AUTOSAR XML (schema 4-0-3)
standard types defined: Boolean, UInt16, UInt32
package /AUTOSAR_Platform/DataConstrs
  range DC_Boolean: raw 0..1
  range DC_UInt16: raw 0..65535
package /PATAC/MSM/ComponentTypes
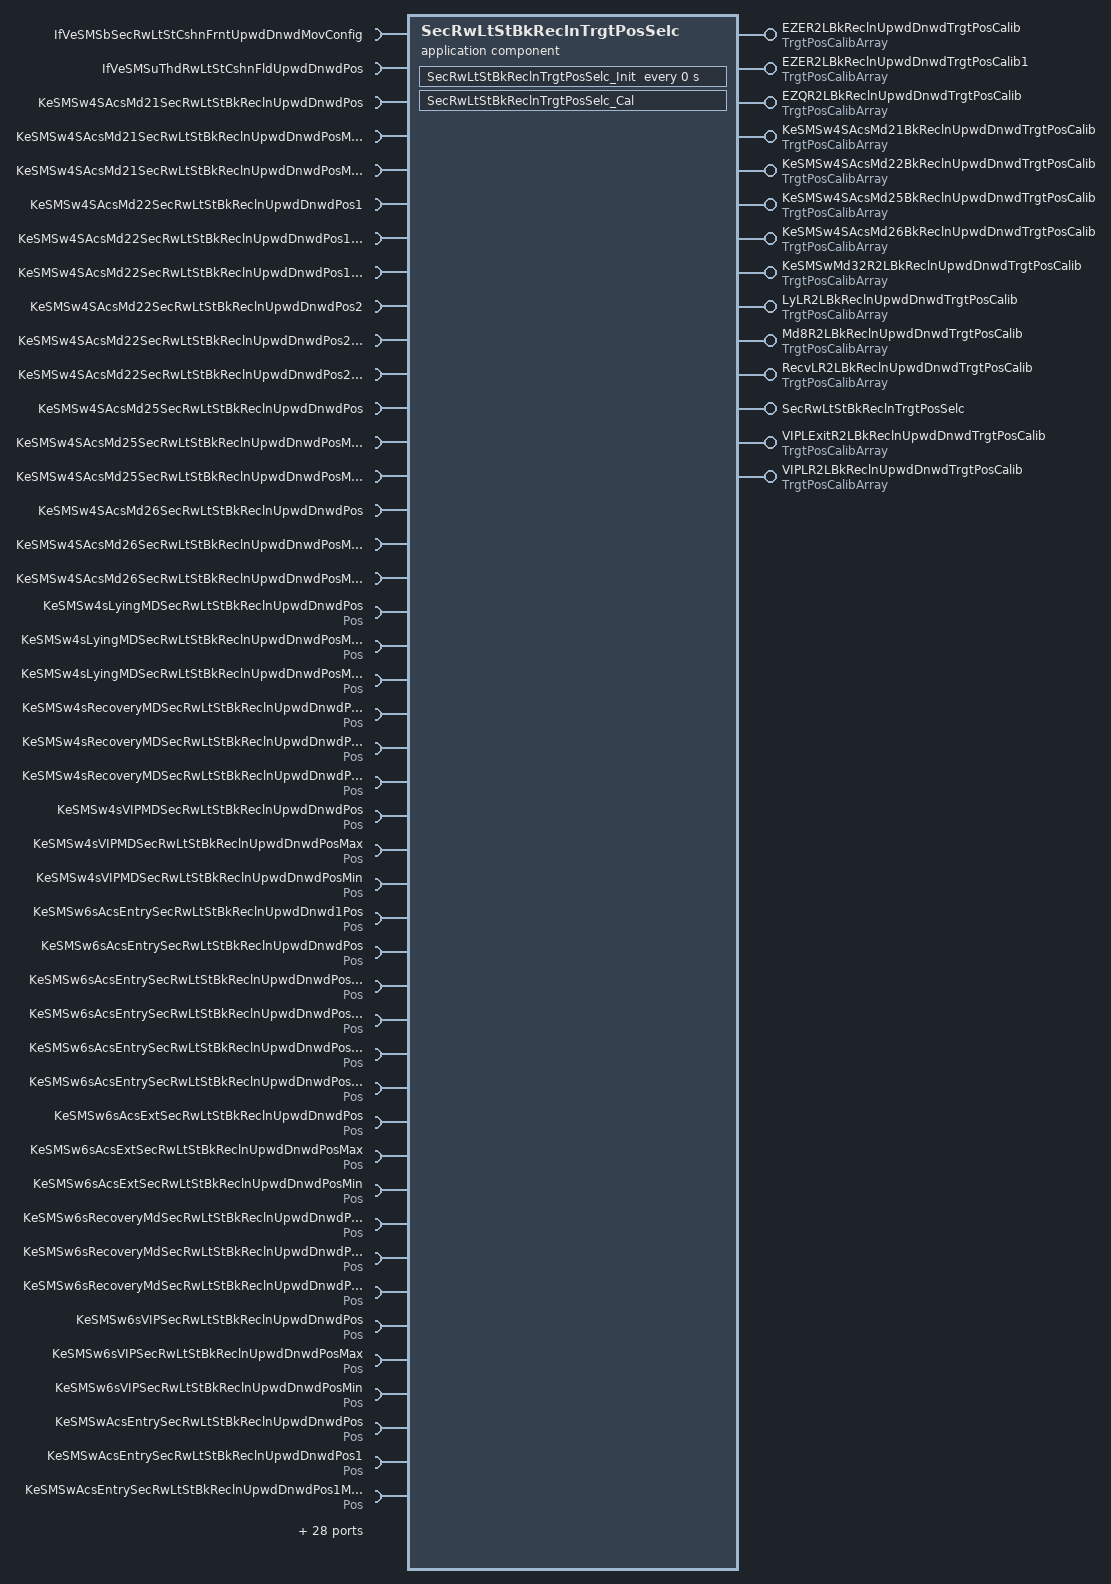
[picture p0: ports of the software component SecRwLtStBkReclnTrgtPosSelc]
  application sw component type SecRwLtStBkReclnTrgtPosSelc
    14 x provide port:
      EZER2LBkReclnUpwdDnwdTrgtPosCalib: nonqueued-sender-com-spec{data-element=TrgtPosArray, init-value=[4095, 4095, 4095]}, provided-interface=TrgtPosCalibArray
      EZER2LBkReclnUpwdDnwdTrgtPosCalib1: nonqueued-sender-com-spec{data-element=TrgtPosArray, init-value=[4095, 4095, 4095]}, provided-interface=TrgtPosCalibArray
      EZQR2LBkReclnUpwdDnwdTrgtPosCalib: nonqueued-sender-com-spec{data-element=TrgtPosArray, init-value=[4095, 4095, 4095]}, provided-interface=TrgtPosCalibArray
      KeSMSw4SAcsMd21BkReclnUpwdDnwdTrgtPosCalib: nonqueued-sender-com-spec{data-element=TrgtPosArray, init-value=[4095, 4095, 4095]}, provided-interface=TrgtPosCalibArray
      KeSMSw4SAcsMd22BkReclnUpwdDnwdTrgtPosCalib: nonqueued-sender-com-spec{data-element=TrgtPosArray, init-value=[4095, 4095, 4095]}, provided-interface=TrgtPosCalibArray
      KeSMSw4SAcsMd25BkReclnUpwdDnwdTrgtPosCalib: nonqueued-sender-com-spec{data-element=TrgtPosArray, init-value=[4095, 4095, 4095]}, provided-interface=TrgtPosCalibArray
      KeSMSw4SAcsMd26BkReclnUpwdDnwdTrgtPosCalib: nonqueued-sender-com-spec{data-element=TrgtPosArray, init-value=[4095, 4095, 4095]}, provided-interface=TrgtPosCalibArray
      KeSMSwMd32R2LBkReclnUpwdDnwdTrgtPosCalib: nonqueued-sender-com-spec{data-element=TrgtPosArray, init-value=[4095, 4095, 4095]}, provided-interface=TrgtPosCalibArray
      LyLR2LBkReclnUpwdDnwdTrgtPosCalib: nonqueued-sender-com-spec{data-element=TrgtPosArray, init-value=[4095, 4095, 4095]}, provided-interface=TrgtPosCalibArray
      Md8R2LBkReclnUpwdDnwdTrgtPosCalib: nonqueued-sender-com-spec{data-element=TrgtPosArray, init-value=[4095, 4095, 4095]}, provided-interface=TrgtPosCalibArray
      RecvLR2LBkReclnUpwdDnwdTrgtPosCalib: nonqueued-sender-com-spec{data-element=TrgtPosArray, init-value=[4095, 4095, 4095]}, provided-interface=TrgtPosCalibArray
      SecRwLtStBkReclnTrgtPosSelc: server-com-spec{operation=Cal, queue-length=1}, provided-interface=SecRwLtStBkReclnTrgtPosSelc
      VIPLExitR2LBkReclnUpwdDnwdTrgtPosCalib: nonqueued-sender-com-spec{data-element=TrgtPosArray, init-value=[4095, 4095, 4095]}, provided-interface=TrgtPosCalibArray
      VIPLR2LBkReclnUpwdDnwdTrgtPosCalib: nonqueued-sender-com-spec{data-element=TrgtPosArray, init-value=[4095, 4095, 4095]}, provided-interface=TrgtPosCalibArray
    72 x require port:
      IfVeSMSbSecRwLtStCshnFrntUpwdDnwdMovConfig: nonqueued-receiver-com-spec{data-element=IfVeSMSbSecRwLtStCshnFrntUpwdDnwdMovConfig/Val, filter=data-filter-type=ALWAYS, init-value=0}, required-interface=IfVeSMSbSecRwLtStCshnFrntUpwdDnwdMovConfig
      IfVeSMSuThdRwLtStCshnFldUpwdDnwdPos: nonqueued-receiver-com-spec{data-element=IfVeSMSuThdRwLtStCshnFldUpwdDnwdPos/Val, filter=data-filter-type=ALWAYS, init-value=0}, required-interface=IfVeSMSuThdRwLtStCshnFldUpwdDnwdPos
      KeSMSw4SAcsMd21SecRwLtStBkReclnUpwdDnwdPos: parameter-require-com-spec{init-value=0, parameter=KeSMSw4SAcsMd21SecRwLtStBkReclnUpwdDnwdPos/Val}, required-interface=KeSMSw4SAcsMd21SecRwLtStBkReclnUpwdDnwdPos
      KeSMSw4SAcsMd21SecRwLtStBkReclnUpwdDnwdPosMax: parameter-require-com-spec{init-value=0, parameter=KeSMSw4SAcsMd21SecRwLtStBkReclnUpwdDnwdPosMax/Val}, required-interface=KeSMSw4SAcsMd21SecRwLtStBkReclnUpwdDnwdPosMax
      KeSMSw4SAcsMd21SecRwLtStBkReclnUpwdDnwdPosMin: parameter-require-com-spec{init-value=0, parameter=KeSMSw4SAcsMd21SecRwLtStBkReclnUpwdDnwdPosMin/Val}, required-interface=KeSMSw4SAcsMd21SecRwLtStBkReclnUpwdDnwdPosMin
      KeSMSw4SAcsMd22SecRwLtStBkReclnUpwdDnwdPos1: parameter-require-com-spec{init-value=0, parameter=KeSMSw4SAcsMd22SecRwLtStBkReclnUpwdDnwdPos1/Val}, required-interface=KeSMSw4SAcsMd22SecRwLtStBkReclnUpwdDnwdPos1
      KeSMSw4SAcsMd22SecRwLtStBkReclnUpwdDnwdPos1Max: parameter-require-com-spec{init-value=0, parameter=KeSMSw4SAcsMd22SecRwLtStBkReclnUpwdDnwdPos1Max/Val}, required-interface=KeSMSw4SAcsMd22SecRwLtStBkReclnUpwdDnwdPos1Max
      KeSMSw4SAcsMd22SecRwLtStBkReclnUpwdDnwdPos1Min: parameter-require-com-spec{init-value=0, parameter=KeSMSw4SAcsMd22SecRwLtStBkReclnUpwdDnwdPos1Min/Val}, required-interface=KeSMSw4SAcsMd22SecRwLtStBkReclnUpwdDnwdPos1Min
      KeSMSw4SAcsMd22SecRwLtStBkReclnUpwdDnwdPos2: parameter-require-com-spec{init-value=0, parameter=KeSMSw4SAcsMd22SecRwLtStBkReclnUpwdDnwdPos2/Val}, required-interface=KeSMSw4SAcsMd22SecRwLtStBkReclnUpwdDnwdPos2
      KeSMSw4SAcsMd22SecRwLtStBkReclnUpwdDnwdPos2Max: parameter-require-com-spec{init-value=0, parameter=KeSMSw4SAcsMd22SecRwLtStBkReclnUpwdDnwdPos2Max/Val}, required-interface=KeSMSw4SAcsMd22SecRwLtStBkReclnUpwdDnwdPos2Max
      KeSMSw4SAcsMd22SecRwLtStBkReclnUpwdDnwdPos2Min: parameter-require-com-spec{init-value=0, parameter=KeSMSw4SAcsMd22SecRwLtStBkReclnUpwdDnwdPos2Min/Val}, required-interface=KeSMSw4SAcsMd22SecRwLtStBkReclnUpwdDnwdPos2Min
      KeSMSw4SAcsMd25SecRwLtStBkReclnUpwdDnwdPos: parameter-require-com-spec{init-value=0, parameter=KeSMSw4SAcsMd25SecRwLtStBkReclnUpwdDnwdPos/Val}, required-interface=KeSMSw4SAcsMd25SecRwLtStBkReclnUpwdDnwdPos
      KeSMSw4SAcsMd25SecRwLtStBkReclnUpwdDnwdPosMax: parameter-require-com-spec{init-value=0, parameter=KeSMSw4SAcsMd25SecRwLtStBkReclnUpwdDnwdPosMax/Val}, required-interface=KeSMSw4SAcsMd25SecRwLtStBkReclnUpwdDnwdPosMax
      KeSMSw4SAcsMd25SecRwLtStBkReclnUpwdDnwdPosMin: parameter-require-com-spec{init-value=0, parameter=KeSMSw4SAcsMd25SecRwLtStBkReclnUpwdDnwdPosMin/Val}, required-interface=KeSMSw4SAcsMd25SecRwLtStBkReclnUpwdDnwdPosMin
      KeSMSw4SAcsMd26SecRwLtStBkReclnUpwdDnwdPos: parameter-require-com-spec{init-value=0, parameter=KeSMSw4SAcsMd26SecRwLtStBkReclnUpwdDnwdPos/Val}, required-interface=KeSMSw4SAcsMd26SecRwLtStBkReclnUpwdDnwdPos
      KeSMSw4SAcsMd26SecRwLtStBkReclnUpwdDnwdPosMax: parameter-require-com-spec{init-value=0, parameter=KeSMSw4SAcsMd26SecRwLtStBkReclnUpwdDnwdPosMax/Val}, required-interface=KeSMSw4SAcsMd26SecRwLtStBkReclnUpwdDnwdPosMax
      KeSMSw4SAcsMd26SecRwLtStBkReclnUpwdDnwdPosMin: parameter-require-com-spec{init-value=0, parameter=KeSMSw4SAcsMd26SecRwLtStBkReclnUpwdDnwdPosMin/Val}, required-interface=KeSMSw4SAcsMd26SecRwLtStBkReclnUpwdDnwdPosMin
      KeSMSw4sLyingMDSecRwLtStBkReclnUpwdDnwdPos: parameter-require-com-spec{init-value=0, parameter=Pos/Val}, required-interface=Pos
      KeSMSw4sLyingMDSecRwLtStBkReclnUpwdDnwdPosMax: parameter-require-com-spec{init-value=0, parameter=Pos/Val}, required-interface=Pos
      KeSMSw4sLyingMDSecRwLtStBkReclnUpwdDnwdPosMin: parameter-require-com-spec{init-value=0, parameter=Pos/Val}, required-interface=Pos
      KeSMSw4sRecoveryMDSecRwLtStBkReclnUpwdDnwdPos: parameter-require-com-spec{init-value=0, parameter=Pos/Val}, required-interface=Pos
      KeSMSw4sRecoveryMDSecRwLtStBkReclnUpwdDnwdPosMax: parameter-require-com-spec{init-value=0, parameter=Pos/Val}, required-interface=Pos
      KeSMSw4sRecoveryMDSecRwLtStBkReclnUpwdDnwdPosMin: parameter-require-com-spec{init-value=0, parameter=Pos/Val}, required-interface=Pos
      KeSMSw4sVIPMDSecRwLtStBkReclnUpwdDnwdPos: parameter-require-com-spec{init-value=0, parameter=Pos/Val}, required-interface=Pos
      KeSMSw4sVIPMDSecRwLtStBkReclnUpwdDnwdPosMax: parameter-require-com-spec{init-value=0, parameter=Pos/Val}, required-interface=Pos
      KeSMSw4sVIPMDSecRwLtStBkReclnUpwdDnwdPosMin: parameter-require-com-spec{init-value=0, parameter=Pos/Val}, required-interface=Pos
      KeSMSw6sAcsEntrySecRwLtStBkReclnUpwdDnwd1Pos: parameter-require-com-spec{init-value=1280, parameter=Pos/Val}, required-interface=Pos
      KeSMSw6sAcsEntrySecRwLtStBkReclnUpwdDnwdPos: parameter-require-com-spec{init-value=1280, parameter=Pos/Val}, required-interface=Pos
      KeSMSw6sAcsEntrySecRwLtStBkReclnUpwdDnwdPos1Max: parameter-require-com-spec{init-value=1280, parameter=Pos/Val}, required-interface=Pos
      KeSMSw6sAcsEntrySecRwLtStBkReclnUpwdDnwdPos1Min: parameter-require-com-spec{init-value=0, parameter=Pos/Val}, required-interface=Pos
      KeSMSw6sAcsEntrySecRwLtStBkReclnUpwdDnwdPosMax: parameter-require-com-spec{init-value=1280, parameter=Pos/Val}, required-interface=Pos
      KeSMSw6sAcsEntrySecRwLtStBkReclnUpwdDnwdPosMin: parameter-require-com-spec{init-value=0, parameter=Pos/Val}, required-interface=Pos
      KeSMSw6sAcsExtSecRwLtStBkReclnUpwdDnwdPos: parameter-require-com-spec{init-value=1280, parameter=Pos/Val}, required-interface=Pos
      KeSMSw6sAcsExtSecRwLtStBkReclnUpwdDnwdPosMax: parameter-require-com-spec{init-value=1280, parameter=Pos/Val}, required-interface=Pos
      KeSMSw6sAcsExtSecRwLtStBkReclnUpwdDnwdPosMin: parameter-require-com-spec{init-value=0, parameter=Pos/Val}, required-interface=Pos
      KeSMSw6sRecoveryMdSecRwLtStBkReclnUpwdDnwdPos: parameter-require-com-spec{init-value=1268, parameter=Pos/Val}, required-interface=Pos
      KeSMSw6sRecoveryMdSecRwLtStBkReclnUpwdDnwdPosMax: parameter-require-com-spec{init-value=1268, parameter=Pos/Val}, required-interface=Pos
      KeSMSw6sRecoveryMdSecRwLtStBkReclnUpwdDnwdPosMin: parameter-require-com-spec{init-value=0, parameter=Pos/Val}, required-interface=Pos
      KeSMSw6sVIPSecRwLtStBkReclnUpwdDnwdPos: parameter-require-com-spec{init-value=1960, parameter=Pos/Val}, required-interface=Pos
      KeSMSw6sVIPSecRwLtStBkReclnUpwdDnwdPosMax: parameter-require-com-spec{init-value=1960, parameter=Pos/Val}, required-interface=Pos
      KeSMSw6sVIPSecRwLtStBkReclnUpwdDnwdPosMin: parameter-require-com-spec{init-value=1960, parameter=Pos/Val}, required-interface=Pos
      KeSMSwAcsEntrySecRwLtStBkReclnUpwdDnwdPos: parameter-require-com-spec{init-value=1280, parameter=Pos/Val}, required-interface=Pos
      KeSMSwAcsEntrySecRwLtStBkReclnUpwdDnwdPos1: parameter-require-com-spec{init-value=1280, parameter=Pos/Val}, required-interface=Pos
      KeSMSwAcsEntrySecRwLtStBkReclnUpwdDnwdPos1Max: parameter-require-com-spec{init-value=1280, parameter=Pos/Val}, required-interface=Pos
      KeSMSwAcsEntrySecRwLtStBkReclnUpwdDnwdPos1Min: parameter-require-com-spec{init-value=0, parameter=Pos/Val}, required-interface=Pos
      KeSMSwAcsEntrySecRwLtStBkReclnUpwdDnwdPosMax: parameter-require-com-spec{init-value=1280, parameter=Pos/Val}, required-interface=Pos
      KeSMSwAcsEntrySecRwLtStBkReclnUpwdDnwdPosMin: parameter-require-com-spec{init-value=0, parameter=Pos/Val}, required-interface=Pos
      KeSMSwAcsExtSecRwLtStBkReclnUpwdDnwdPos: parameter-require-com-spec{init-value=1280, parameter=Pos/Val}, required-interface=Pos
      KeSMSwAcsExtSecRwLtStBkReclnUpwdDnwdPosMax: parameter-require-com-spec{init-value=1280, parameter=Pos/Val}, required-interface=Pos
      KeSMSwAcsExtSecRwLtStBkReclnUpwdDnwdPosMin: parameter-require-com-spec{init-value=0, parameter=Pos/Val}, required-interface=Pos
      KeSMSwAcsMd32SecRwLtStBkReclnUpwdDnwdPos: parameter-require-com-spec{init-value=0, parameter=Pos/Val}, required-interface=Pos
      KeSMSwAcsMd32SecRwLtStBkReclnUpwdDnwdPos1: parameter-require-com-spec{init-value=0, parameter=Pos/Val}, required-interface=Pos
      KeSMSwAcsMd32SecRwLtStBkReclnUpwdDnwdPos1Max: parameter-require-com-spec{init-value=0, parameter=Pos/Val}, required-interface=Pos
      KeSMSwAcsMd32SecRwLtStBkReclnUpwdDnwdPos1Min: parameter-require-com-spec{init-value=0, parameter=Pos/Val}, required-interface=Pos
      KeSMSwAcsMd32SecRwLtStBkReclnUpwdDnwdPosMax: parameter-require-com-spec{init-value=0, parameter=Pos/Val}, required-interface=Pos
      KeSMSwAcsMd32SecRwLtStBkReclnUpwdDnwdPosMin: parameter-require-com-spec{init-value=0, parameter=Pos/Val}, required-interface=Pos
      KeSMSwAcsMd8SecRwLtStBkReclnUpwdDnwdPos: parameter-require-com-spec{init-value=0, parameter=Pos/Val}, required-interface=Pos
      KeSMSwAcsMd8SecRwLtStBkReclnUpwdDnwdPosMax: parameter-require-com-spec{init-value=0, parameter=Pos/Val}, required-interface=Pos
      KeSMSwAcsMd8SecRwLtStBkReclnUpwdDnwdPosMin: parameter-require-com-spec{init-value=0, parameter=Pos/Val}, required-interface=Pos
      KeSMSwRecoveryMdSecRwLtStBkReclnUpwdDnwdPos: parameter-require-com-spec{init-value=1268, parameter=Pos/Val}, required-interface=Pos
      KeSMSwRecoveryMdSecRwLtStBkReclnUpwdDnwdPosMax: parameter-require-com-spec{init-value=1268, parameter=Pos/Val}, required-interface=Pos
      KeSMSwRecoveryMdSecRwLtStBkReclnUpwdDnwdPosMin: parameter-require-com-spec{init-value=0, parameter=Pos/Val}, required-interface=Pos
      KeSMSwVIPSecRwLtStBkReclnUpwdDnwdPos: parameter-require-com-spec{init-value=1960, parameter=Pos/Val}, required-interface=Pos
      KeSMSwVIPSecRwLtStBkReclnUpwdDnwdPosMax: parameter-require-com-spec{init-value=1960, parameter=Pos/Val}, required-interface=Pos
      KeSMSwVIPSecRwLtStBkReclnUpwdDnwdPosMin: parameter-require-com-spec{init-value=1960, parameter=Pos/Val}, required-interface=Pos
      modestate32: nonqueued-receiver-com-spec{data-element=modestate32/Val, filter=data-filter-type=ALWAYS, init-value=0}, required-interface=modestate32
      R2LBkReclinFirstStepPassFlg: nonqueued-receiver-com-spec{data-element=R2LBkReclinFirstStepPassFlg/Val, filter=data-filter-type=ALWAYS, init-value=0}, required-interface=R2LBkReclinFirstStepPassFlg
      R2LMdSeatOccupied: nonqueued-receiver-com-spec{data-element=MdSeatOccupied/Val, filter=data-filter-type=ALWAYS, init-value=0}, required-interface=MdSeatOccupied
      StNumFlg: required-interface=StNumFlg
        required-com-specs:
          data-element=Is4s, filter=data-filter-type=ALWAYS, init-value=0
          data-element=Is6s, filter=data-filter-type=ALWAYS, init-value=0
          data-element=Is6s7s, filter=data-filter-type=ALWAYS, init-value=0
          data-element=Is7s, filter=data-filter-type=ALWAYS, init-value=0
      ThdRwLtStCshnFldStgDone: nonqueued-receiver-com-spec{data-element=StgDone/Val, filter=data-filter-type=ALWAYS, init-value=0}, required-interface=StgDone
      VIPL557TrgtPos: required-com-specs=[VIPL557TrgtPos/Get, VIPL557TrgtPos/Set], required-interface=VIPL557TrgtPos
      VIPLExit557TrgtPos: required-com-specs=[VIPLExit557TrgtPos/Get, VIPLExit557TrgtPos/Set], required-interface=VIPLExit557TrgtPos
    behavior SecRwLtStBkReclnTrgtPosSelc_InternalBehavior
      operation invoked event OIT_SecRwLtStBkReclnTrgtPosSelc_Cal_SecRwLtStBkReclnTrgtPosSelc_Cal: start-on-event=SecRwLtStBkReclnTrgtPosSelc_Cal, operation=SecRwLtStBkReclnTrgtPosSelc.Cal
      timing event SecRwLtStBkReclnTrgtPosSelc_InitEvent: start-on-event=SecRwLtStBkReclnTrgtPosSelc_Init, period=0
      runnable SecRwLtStBkReclnTrgtPosSelc_Cal
        data-receive-point-by-arguments:
          10 x access:
            REC_IfVeSMSbSecRwLtStCshnFrntUpwdDnwdMovConfig_Val: accessed-variable=IfVeSMSbSecRwLtStCshnFrntUpwdDnwdMovConfig.Val
            REC_IfVeSMSuThdRwLtStCshnFldUpwdDnwdPos_Val: accessed-variable=IfVeSMSuThdRwLtStCshnFldUpwdDnwdPos.Val
            REC_modestate32_Val: accessed-variable=modestate32.Val
            REC_R2LBkReclinFirstStepPassFlg_Val: accessed-variable=R2LBkReclinFirstStepPassFlg.Val
            REC_R2LMdSeatOccupied_Val: accessed-variable=R2LMdSeatOccupied.Val
            REC_StNumFlg_Is4s: accessed-variable=StNumFlg.Is4s
            REC_StNumFlg_Is6s: accessed-variable=StNumFlg.Is6s
            REC_StNumFlg_Is6s7s: accessed-variable=StNumFlg.Is6s7s
            REC_StNumFlg_Is7s: accessed-variable=StNumFlg.Is7s
            REC_ThdRwLtStCshnFldStgDone_Val: accessed-variable=ThdRwLtStCshnFldStgDone.Val
        data-send-points:
          13 x access:
            SEND_EZER2LBkReclnUpwdDnwdTrgtPosCalib_TrgtPosArray: accessed-variable=EZER2LBkReclnUpwdDnwdTrgtPosCalib.TrgtPosArray
            SEND_EZER2LBkReclnUpwdDnwdTrgtPosCalib1_TrgtPosArray: accessed-variable=EZER2LBkReclnUpwdDnwdTrgtPosCalib1.TrgtPosArray
            SEND_EZQR2LBkReclnUpwdDnwdTrgtPosCalib_TrgtPosArray: accessed-variable=EZQR2LBkReclnUpwdDnwdTrgtPosCalib.TrgtPosArray
            SEND_KeSMSw4SAcsMd21BkReclnUpwdDnwdTrgtPosCalib_TrgtPosArray: accessed-variable=KeSMSw4SAcsMd21BkReclnUpwdDnwdTrgtPosCalib.TrgtPosArray
            SEND_KeSMSw4SAcsMd22BkReclnUpwdDnwdTrgtPosCalib_TrgtPosArray: accessed-variable=KeSMSw4SAcsMd22BkReclnUpwdDnwdTrgtPosCalib.TrgtPosArray
            SEND_KeSMSw4SAcsMd25BkReclnUpwdDnwdTrgtPosCalib_TrgtPosArray: accessed-variable=KeSMSw4SAcsMd25BkReclnUpwdDnwdTrgtPosCalib.TrgtPosArray
            SEND_KeSMSw4SAcsMd26BkReclnUpwdDnwdTrgtPosCalib_TrgtPosArray: accessed-variable=KeSMSw4SAcsMd26BkReclnUpwdDnwdTrgtPosCalib.TrgtPosArray
            SEND_KeSMSwMd32R2LBkReclnUpwdDnwdTrgtPosCalib_TrgtPosArray: accessed-variable=KeSMSwMd32R2LBkReclnUpwdDnwdTrgtPosCalib.TrgtPosArray
            SEND_LyLR2LBkReclnUpwdDnwdTrgtPosCalib_TrgtPosArray: accessed-variable=LyLR2LBkReclnUpwdDnwdTrgtPosCalib.TrgtPosArray
            SEND_Md8R2LBkReclnUpwdDnwdTrgtPosCalib_TrgtPosArray: accessed-variable=Md8R2LBkReclnUpwdDnwdTrgtPosCalib.TrgtPosArray
            SEND_RecvLR2LBkReclnUpwdDnwdTrgtPosCalib_TrgtPosArray: accessed-variable=RecvLR2LBkReclnUpwdDnwdTrgtPosCalib.TrgtPosArray
            SEND_VIPLExitR2LBkReclnUpwdDnwdTrgtPosCalib_TrgtPosArray: accessed-variable=VIPLExitR2LBkReclnUpwdDnwdTrgtPosCalib.TrgtPosArray
            SEND_VIPLR2LBkReclnUpwdDnwdTrgtPosCalib_TrgtPosArray: accessed-variable=VIPLR2LBkReclnUpwdDnwdTrgtPosCalib.TrgtPosArray
        63 x parameter access:
          PA_KeSMSw4SAcsMd21SecRwLtStBkReclnUpwdDnwdPos_Val: accessed-parameter=KeSMSw4SAcsMd21SecRwLtStBkReclnUpwdDnwdPos.Val
          PA_KeSMSw4SAcsMd21SecRwLtStBkReclnUpwdDnwdPosMax_Val: accessed-parameter=KeSMSw4SAcsMd21SecRwLtStBkReclnUpwdDnwdPosMax.Val
          PA_KeSMSw4SAcsMd21SecRwLtStBkReclnUpwdDnwdPosMin_Val: accessed-parameter=KeSMSw4SAcsMd21SecRwLtStBkReclnUpwdDnwdPosMin.Val
          PA_KeSMSw4SAcsMd22SecRwLtStBkReclnUpwdDnwdPos1_Val: accessed-parameter=KeSMSw4SAcsMd22SecRwLtStBkReclnUpwdDnwdPos1.Val
          PA_KeSMSw4SAcsMd22SecRwLtStBkReclnUpwdDnwdPos1Max_Val: accessed-parameter=KeSMSw4SAcsMd22SecRwLtStBkReclnUpwdDnwdPos1Max.Val
          PA_KeSMSw4SAcsMd22SecRwLtStBkReclnUpwdDnwdPos1Min_Val: accessed-parameter=KeSMSw4SAcsMd22SecRwLtStBkReclnUpwdDnwdPos1Min.Val
          PA_KeSMSw4SAcsMd22SecRwLtStBkReclnUpwdDnwdPos2_Val: accessed-parameter=KeSMSw4SAcsMd22SecRwLtStBkReclnUpwdDnwdPos2.Val
          PA_KeSMSw4SAcsMd22SecRwLtStBkReclnUpwdDnwdPos2Max_Val: accessed-parameter=KeSMSw4SAcsMd22SecRwLtStBkReclnUpwdDnwdPos2Max.Val
          PA_KeSMSw4SAcsMd22SecRwLtStBkReclnUpwdDnwdPos2Min_Val: accessed-parameter=KeSMSw4SAcsMd22SecRwLtStBkReclnUpwdDnwdPos2Min.Val
          PA_KeSMSw4SAcsMd25SecRwLtStBkReclnUpwdDnwdPos_Val: accessed-parameter=KeSMSw4SAcsMd25SecRwLtStBkReclnUpwdDnwdPos.Val
          PA_KeSMSw4SAcsMd25SecRwLtStBkReclnUpwdDnwdPosMax_Val: accessed-parameter=KeSMSw4SAcsMd25SecRwLtStBkReclnUpwdDnwdPosMax.Val
          PA_KeSMSw4SAcsMd25SecRwLtStBkReclnUpwdDnwdPosMin_Val: accessed-parameter=KeSMSw4SAcsMd25SecRwLtStBkReclnUpwdDnwdPosMin.Val
          PA_KeSMSw4SAcsMd26SecRwLtStBkReclnUpwdDnwdPos_Val: accessed-parameter=KeSMSw4SAcsMd26SecRwLtStBkReclnUpwdDnwdPos.Val
          PA_KeSMSw4SAcsMd26SecRwLtStBkReclnUpwdDnwdPosMax_Val: accessed-parameter=KeSMSw4SAcsMd26SecRwLtStBkReclnUpwdDnwdPosMax.Val
          PA_KeSMSw4SAcsMd26SecRwLtStBkReclnUpwdDnwdPosMin_Val: accessed-parameter=KeSMSw4SAcsMd26SecRwLtStBkReclnUpwdDnwdPosMin.Val
          PA_KeSMSw4sLyingMDSecRwLtStBkReclnUpwdDnwdPos_Val: accessed-parameter=KeSMSw4sLyingMDSecRwLtStBkReclnUpwdDnwdPos.Val
          PA_KeSMSw4sLyingMDSecRwLtStBkReclnUpwdDnwdPosMax_Val: accessed-parameter=KeSMSw4sLyingMDSecRwLtStBkReclnUpwdDnwdPosMax.Val
          PA_KeSMSw4sLyingMDSecRwLtStBkReclnUpwdDnwdPosMin_Val: accessed-parameter=KeSMSw4sLyingMDSecRwLtStBkReclnUpwdDnwdPosMin.Val
          PA_KeSMSw4sRecoveryMDSecRwLtStBkReclnUpwdDnwdPos_Val: accessed-parameter=KeSMSw4sRecoveryMDSecRwLtStBkReclnUpwdDnwdPos.Val
          PA_KeSMSw4sRecoveryMDSecRwLtStBkReclnUpwdDnwdPosMax_Val: accessed-parameter=KeSMSw4sRecoveryMDSecRwLtStBkReclnUpwdDnwdPosMax.Val
          PA_KeSMSw4sRecoveryMDSecRwLtStBkReclnUpwdDnwdPosMin_Val: accessed-parameter=KeSMSw4sRecoveryMDSecRwLtStBkReclnUpwdDnwdPosMin.Val
          PA_KeSMSw4sVIPMDSecRwLtStBkReclnUpwdDnwdPos_Val: accessed-parameter=KeSMSw4sVIPMDSecRwLtStBkReclnUpwdDnwdPos.Val
          PA_KeSMSw4sVIPMDSecRwLtStBkReclnUpwdDnwdPosMax_Val: accessed-parameter=KeSMSw4sVIPMDSecRwLtStBkReclnUpwdDnwdPosMax.Val
          PA_KeSMSw4sVIPMDSecRwLtStBkReclnUpwdDnwdPosMin_Val: accessed-parameter=KeSMSw4sVIPMDSecRwLtStBkReclnUpwdDnwdPosMin.Val
          PA_KeSMSw6sAcsEntrySecRwLtStBkReclnUpwdDnwd1Pos_Val: accessed-parameter=KeSMSw6sAcsEntrySecRwLtStBkReclnUpwdDnwd1Pos.Val
          PA_KeSMSw6sAcsEntrySecRwLtStBkReclnUpwdDnwdPos_Val: accessed-parameter=KeSMSw6sAcsEntrySecRwLtStBkReclnUpwdDnwdPos.Val
          PA_KeSMSw6sAcsEntrySecRwLtStBkReclnUpwdDnwdPos1Max_Val: accessed-parameter=KeSMSw6sAcsEntrySecRwLtStBkReclnUpwdDnwdPos1Max.Val
          PA_KeSMSw6sAcsEntrySecRwLtStBkReclnUpwdDnwdPos1Min_Val: accessed-parameter=KeSMSw6sAcsEntrySecRwLtStBkReclnUpwdDnwdPos1Min.Val
          PA_KeSMSw6sAcsEntrySecRwLtStBkReclnUpwdDnwdPosMax_Val: accessed-parameter=KeSMSw6sAcsEntrySecRwLtStBkReclnUpwdDnwdPosMax.Val
          PA_KeSMSw6sAcsEntrySecRwLtStBkReclnUpwdDnwdPosMin_Val: accessed-parameter=KeSMSw6sAcsEntrySecRwLtStBkReclnUpwdDnwdPosMin.Val
          PA_KeSMSw6sAcsExtSecRwLtStBkReclnUpwdDnwdPos_Val: accessed-parameter=KeSMSw6sAcsExtSecRwLtStBkReclnUpwdDnwdPos.Val
          PA_KeSMSw6sAcsExtSecRwLtStBkReclnUpwdDnwdPosMax_Val: accessed-parameter=KeSMSw6sAcsExtSecRwLtStBkReclnUpwdDnwdPosMax.Val
          PA_KeSMSw6sAcsExtSecRwLtStBkReclnUpwdDnwdPosMin_Val: accessed-parameter=KeSMSw6sAcsExtSecRwLtStBkReclnUpwdDnwdPosMin.Val
          PA_KeSMSw6sRecoveryMdSecRwLtStBkReclnUpwdDnwdPos_Val: accessed-parameter=KeSMSw6sRecoveryMdSecRwLtStBkReclnUpwdDnwdPos.Val
          PA_KeSMSw6sRecoveryMdSecRwLtStBkReclnUpwdDnwdPosMax_Val: accessed-parameter=KeSMSw6sRecoveryMdSecRwLtStBkReclnUpwdDnwdPosMax.Val
          PA_KeSMSw6sRecoveryMdSecRwLtStBkReclnUpwdDnwdPosMin_Val: accessed-parameter=KeSMSw6sRecoveryMdSecRwLtStBkReclnUpwdDnwdPosMin.Val
          PA_KeSMSw6sVIPSecRwLtStBkReclnUpwdDnwdPos_Val: accessed-parameter=KeSMSw6sVIPSecRwLtStBkReclnUpwdDnwdPos.Val
          PA_KeSMSw6sVIPSecRwLtStBkReclnUpwdDnwdPosMax_Val: accessed-parameter=KeSMSw6sVIPSecRwLtStBkReclnUpwdDnwdPosMax.Val
          PA_KeSMSw6sVIPSecRwLtStBkReclnUpwdDnwdPosMin_Val: accessed-parameter=KeSMSw6sVIPSecRwLtStBkReclnUpwdDnwdPosMin.Val
          PA_KeSMSwAcsEntrySecRwLtStBkReclnUpwdDnwdPos_Val: accessed-parameter=KeSMSwAcsEntrySecRwLtStBkReclnUpwdDnwdPos.Val
          PA_KeSMSwAcsEntrySecRwLtStBkReclnUpwdDnwdPos1_Val: accessed-parameter=KeSMSwAcsEntrySecRwLtStBkReclnUpwdDnwdPos1.Val
          PA_KeSMSwAcsEntrySecRwLtStBkReclnUpwdDnwdPos1Max_Val: accessed-parameter=KeSMSwAcsEntrySecRwLtStBkReclnUpwdDnwdPos1Max.Val
          PA_KeSMSwAcsEntrySecRwLtStBkReclnUpwdDnwdPos1Min_Val: accessed-parameter=KeSMSwAcsEntrySecRwLtStBkReclnUpwdDnwdPos1Min.Val
          PA_KeSMSwAcsEntrySecRwLtStBkReclnUpwdDnwdPosMax_Val: accessed-parameter=KeSMSwAcsEntrySecRwLtStBkReclnUpwdDnwdPosMax.Val
          PA_KeSMSwAcsEntrySecRwLtStBkReclnUpwdDnwdPosMin_Val: accessed-parameter=KeSMSwAcsEntrySecRwLtStBkReclnUpwdDnwdPosMin.Val
          PA_KeSMSwAcsExtSecRwLtStBkReclnUpwdDnwdPos_Val: accessed-parameter=KeSMSwAcsExtSecRwLtStBkReclnUpwdDnwdPos.Val
          PA_KeSMSwAcsExtSecRwLtStBkReclnUpwdDnwdPosMax_Val: accessed-parameter=KeSMSwAcsExtSecRwLtStBkReclnUpwdDnwdPosMax.Val
          PA_KeSMSwAcsExtSecRwLtStBkReclnUpwdDnwdPosMin_Val: accessed-parameter=KeSMSwAcsExtSecRwLtStBkReclnUpwdDnwdPosMin.Val
          PA_KeSMSwAcsMd32SecRwLtStBkReclnUpwdDnwdPos_Val: accessed-parameter=KeSMSwAcsMd32SecRwLtStBkReclnUpwdDnwdPos.Val
          PA_KeSMSwAcsMd32SecRwLtStBkReclnUpwdDnwdPos1_Val: accessed-parameter=KeSMSwAcsMd32SecRwLtStBkReclnUpwdDnwdPos1.Val
          PA_KeSMSwAcsMd32SecRwLtStBkReclnUpwdDnwdPos1Max_Val: accessed-parameter=KeSMSwAcsMd32SecRwLtStBkReclnUpwdDnwdPos1Max.Val
          PA_KeSMSwAcsMd32SecRwLtStBkReclnUpwdDnwdPos1Min_Val: accessed-parameter=KeSMSwAcsMd32SecRwLtStBkReclnUpwdDnwdPos1Min.Val
          PA_KeSMSwAcsMd32SecRwLtStBkReclnUpwdDnwdPosMax_Val: accessed-parameter=KeSMSwAcsMd32SecRwLtStBkReclnUpwdDnwdPosMax.Val
          PA_KeSMSwAcsMd32SecRwLtStBkReclnUpwdDnwdPosMin_Val: accessed-parameter=KeSMSwAcsMd32SecRwLtStBkReclnUpwdDnwdPosMin.Val
          PA_KeSMSwAcsMd8SecRwLtStBkReclnUpwdDnwdPos_Val: accessed-parameter=KeSMSwAcsMd8SecRwLtStBkReclnUpwdDnwdPos.Val
          PA_KeSMSwAcsMd8SecRwLtStBkReclnUpwdDnwdPosMax_Val: accessed-parameter=KeSMSwAcsMd8SecRwLtStBkReclnUpwdDnwdPosMax.Val
          PA_KeSMSwAcsMd8SecRwLtStBkReclnUpwdDnwdPosMin_Val: accessed-parameter=KeSMSwAcsMd8SecRwLtStBkReclnUpwdDnwdPosMin.Val
          PA_KeSMSwRecoveryMdSecRwLtStBkReclnUpwdDnwdPos_Val: accessed-parameter=KeSMSwRecoveryMdSecRwLtStBkReclnUpwdDnwdPos.Val
          PA_KeSMSwRecoveryMdSecRwLtStBkReclnUpwdDnwdPosMax_Val: accessed-parameter=KeSMSwRecoveryMdSecRwLtStBkReclnUpwdDnwdPosMax.Val
          PA_KeSMSwRecoveryMdSecRwLtStBkReclnUpwdDnwdPosMin_Val: accessed-parameter=KeSMSwRecoveryMdSecRwLtStBkReclnUpwdDnwdPosMin.Val
          PA_KeSMSwVIPSecRwLtStBkReclnUpwdDnwdPos_Val: accessed-parameter=KeSMSwVIPSecRwLtStBkReclnUpwdDnwdPos.Val
          PA_KeSMSwVIPSecRwLtStBkReclnUpwdDnwdPosMax_Val: accessed-parameter=KeSMSwVIPSecRwLtStBkReclnUpwdDnwdPosMax.Val
          PA_KeSMSwVIPSecRwLtStBkReclnUpwdDnwdPosMin_Val: accessed-parameter=KeSMSwVIPSecRwLtStBkReclnUpwdDnwdPosMin.Val
        sync call SC_VIPL557TrgtPos_Get: operation=VIPL557TrgtPos.Get, timeout=0
        sync call SC_VIPLExit557TrgtPos_Get: operation=VIPLExit557TrgtPos.Get, timeout=0
      runnable SecRwLtStBkReclnTrgtPosSelc_Init
        63 x parameter access:
          PA_KeSMSw4SAcsMd21SecRwLtStBkReclnUpwdDnwdPos_Val: accessed-parameter=KeSMSw4SAcsMd21SecRwLtStBkReclnUpwdDnwdPos.Val
          PA_KeSMSw4SAcsMd21SecRwLtStBkReclnUpwdDnwdPosMax_Val: accessed-parameter=KeSMSw4SAcsMd21SecRwLtStBkReclnUpwdDnwdPosMax.Val
          PA_KeSMSw4SAcsMd21SecRwLtStBkReclnUpwdDnwdPosMin_Val: accessed-parameter=KeSMSw4SAcsMd21SecRwLtStBkReclnUpwdDnwdPosMin.Val
          PA_KeSMSw4SAcsMd22SecRwLtStBkReclnUpwdDnwdPos1_Val: accessed-parameter=KeSMSw4SAcsMd22SecRwLtStBkReclnUpwdDnwdPos1.Val
          PA_KeSMSw4SAcsMd22SecRwLtStBkReclnUpwdDnwdPos1Max_Val: accessed-parameter=KeSMSw4SAcsMd22SecRwLtStBkReclnUpwdDnwdPos1Max.Val
          PA_KeSMSw4SAcsMd22SecRwLtStBkReclnUpwdDnwdPos1Min_Val: accessed-parameter=KeSMSw4SAcsMd22SecRwLtStBkReclnUpwdDnwdPos1Min.Val
          PA_KeSMSw4SAcsMd22SecRwLtStBkReclnUpwdDnwdPos2_Val: accessed-parameter=KeSMSw4SAcsMd22SecRwLtStBkReclnUpwdDnwdPos2.Val
          PA_KeSMSw4SAcsMd22SecRwLtStBkReclnUpwdDnwdPos2Max_Val: accessed-parameter=KeSMSw4SAcsMd22SecRwLtStBkReclnUpwdDnwdPos2Max.Val
          PA_KeSMSw4SAcsMd22SecRwLtStBkReclnUpwdDnwdPos2Min_Val: accessed-parameter=KeSMSw4SAcsMd22SecRwLtStBkReclnUpwdDnwdPos2Min.Val
          PA_KeSMSw4SAcsMd25SecRwLtStBkReclnUpwdDnwdPos_Val: accessed-parameter=KeSMSw4SAcsMd25SecRwLtStBkReclnUpwdDnwdPos.Val
          PA_KeSMSw4SAcsMd25SecRwLtStBkReclnUpwdDnwdPosMax_Val: accessed-parameter=KeSMSw4SAcsMd25SecRwLtStBkReclnUpwdDnwdPosMax.Val
          PA_KeSMSw4SAcsMd25SecRwLtStBkReclnUpwdDnwdPosMin_Val: accessed-parameter=KeSMSw4SAcsMd25SecRwLtStBkReclnUpwdDnwdPosMin.Val
          PA_KeSMSw4SAcsMd26SecRwLtStBkReclnUpwdDnwdPos_Val: accessed-parameter=KeSMSw4SAcsMd26SecRwLtStBkReclnUpwdDnwdPos.Val
          PA_KeSMSw4SAcsMd26SecRwLtStBkReclnUpwdDnwdPosMax_Val: accessed-parameter=KeSMSw4SAcsMd26SecRwLtStBkReclnUpwdDnwdPosMax.Val
          PA_KeSMSw4SAcsMd26SecRwLtStBkReclnUpwdDnwdPosMin_Val: accessed-parameter=KeSMSw4SAcsMd26SecRwLtStBkReclnUpwdDnwdPosMin.Val
          PA_KeSMSw4sLyingMDSecRwLtStBkReclnUpwdDnwdPos_Val: accessed-parameter=KeSMSw4sLyingMDSecRwLtStBkReclnUpwdDnwdPos.Val
          PA_KeSMSw4sLyingMDSecRwLtStBkReclnUpwdDnwdPosMax_Val: accessed-parameter=KeSMSw4sLyingMDSecRwLtStBkReclnUpwdDnwdPosMax.Val
          PA_KeSMSw4sLyingMDSecRwLtStBkReclnUpwdDnwdPosMin_Val: accessed-parameter=KeSMSw4sLyingMDSecRwLtStBkReclnUpwdDnwdPosMin.Val
          PA_KeSMSw4sRecoveryMDSecRwLtStBkReclnUpwdDnwdPos_Val: accessed-parameter=KeSMSw4sRecoveryMDSecRwLtStBkReclnUpwdDnwdPos.Val
          PA_KeSMSw4sRecoveryMDSecRwLtStBkReclnUpwdDnwdPosMax_Val: accessed-parameter=KeSMSw4sRecoveryMDSecRwLtStBkReclnUpwdDnwdPosMax.Val
          PA_KeSMSw4sRecoveryMDSecRwLtStBkReclnUpwdDnwdPosMin_Val: accessed-parameter=KeSMSw4sRecoveryMDSecRwLtStBkReclnUpwdDnwdPosMin.Val
          PA_KeSMSw4sVIPMDSecRwLtStBkReclnUpwdDnwdPos_Val: accessed-parameter=KeSMSw4sVIPMDSecRwLtStBkReclnUpwdDnwdPos.Val
          PA_KeSMSw4sVIPMDSecRwLtStBkReclnUpwdDnwdPosMax_Val: accessed-parameter=KeSMSw4sVIPMDSecRwLtStBkReclnUpwdDnwdPosMax.Val
          PA_KeSMSw4sVIPMDSecRwLtStBkReclnUpwdDnwdPosMin_Val: accessed-parameter=KeSMSw4sVIPMDSecRwLtStBkReclnUpwdDnwdPosMin.Val
          PA_KeSMSw6sAcsEntrySecRwLtStBkReclnUpwdDnwd1Pos_Val: accessed-parameter=KeSMSw6sAcsEntrySecRwLtStBkReclnUpwdDnwd1Pos.Val
          PA_KeSMSw6sAcsEntrySecRwLtStBkReclnUpwdDnwdPos_Val: accessed-parameter=KeSMSw6sAcsEntrySecRwLtStBkReclnUpwdDnwdPos.Val
          PA_KeSMSw6sAcsEntrySecRwLtStBkReclnUpwdDnwdPos1Max_Val: accessed-parameter=KeSMSw6sAcsEntrySecRwLtStBkReclnUpwdDnwdPos1Max.Val
          PA_KeSMSw6sAcsEntrySecRwLtStBkReclnUpwdDnwdPos1Min_Val: accessed-parameter=KeSMSw6sAcsEntrySecRwLtStBkReclnUpwdDnwdPos1Min.Val
          PA_KeSMSw6sAcsEntrySecRwLtStBkReclnUpwdDnwdPosMax_Val: accessed-parameter=KeSMSw6sAcsEntrySecRwLtStBkReclnUpwdDnwdPosMax.Val
          PA_KeSMSw6sAcsEntrySecRwLtStBkReclnUpwdDnwdPosMin_Val: accessed-parameter=KeSMSw6sAcsEntrySecRwLtStBkReclnUpwdDnwdPosMin.Val
          PA_KeSMSw6sAcsExtSecRwLtStBkReclnUpwdDnwdPos_Val: accessed-parameter=KeSMSw6sAcsExtSecRwLtStBkReclnUpwdDnwdPos.Val
          PA_KeSMSw6sAcsExtSecRwLtStBkReclnUpwdDnwdPosMax_Val: accessed-parameter=KeSMSw6sAcsExtSecRwLtStBkReclnUpwdDnwdPosMax.Val
          PA_KeSMSw6sAcsExtSecRwLtStBkReclnUpwdDnwdPosMin_Val: accessed-parameter=KeSMSw6sAcsExtSecRwLtStBkReclnUpwdDnwdPosMin.Val
          PA_KeSMSw6sRecoveryMdSecRwLtStBkReclnUpwdDnwdPos_Val: accessed-parameter=KeSMSw6sRecoveryMdSecRwLtStBkReclnUpwdDnwdPos.Val
          PA_KeSMSw6sRecoveryMdSecRwLtStBkReclnUpwdDnwdPosMax_Val: accessed-parameter=KeSMSw6sRecoveryMdSecRwLtStBkReclnUpwdDnwdPosMax.Val
          PA_KeSMSw6sRecoveryMdSecRwLtStBkReclnUpwdDnwdPosMin_Val: accessed-parameter=KeSMSw6sRecoveryMdSecRwLtStBkReclnUpwdDnwdPosMin.Val
          PA_KeSMSw6sVIPSecRwLtStBkReclnUpwdDnwdPos_Val: accessed-parameter=KeSMSw6sVIPSecRwLtStBkReclnUpwdDnwdPos.Val
          PA_KeSMSw6sVIPSecRwLtStBkReclnUpwdDnwdPosMax_Val: accessed-parameter=KeSMSw6sVIPSecRwLtStBkReclnUpwdDnwdPosMax.Val
          PA_KeSMSw6sVIPSecRwLtStBkReclnUpwdDnwdPosMin_Val: accessed-parameter=KeSMSw6sVIPSecRwLtStBkReclnUpwdDnwdPosMin.Val
          PA_KeSMSwAcsEntrySecRwLtStBkReclnUpwdDnwdPos_Val: accessed-parameter=KeSMSwAcsEntrySecRwLtStBkReclnUpwdDnwdPos.Val
          PA_KeSMSwAcsEntrySecRwLtStBkReclnUpwdDnwdPos1_Val: accessed-parameter=KeSMSwAcsEntrySecRwLtStBkReclnUpwdDnwdPos1.Val
          PA_KeSMSwAcsEntrySecRwLtStBkReclnUpwdDnwdPos1Max_Val: accessed-parameter=KeSMSwAcsEntrySecRwLtStBkReclnUpwdDnwdPos1Max.Val
          PA_KeSMSwAcsEntrySecRwLtStBkReclnUpwdDnwdPos1Min_Val: accessed-parameter=KeSMSwAcsEntrySecRwLtStBkReclnUpwdDnwdPos1Min.Val
          PA_KeSMSwAcsEntrySecRwLtStBkReclnUpwdDnwdPosMax_Val: accessed-parameter=KeSMSwAcsEntrySecRwLtStBkReclnUpwdDnwdPosMax.Val
          PA_KeSMSwAcsEntrySecRwLtStBkReclnUpwdDnwdPosMin_Val: accessed-parameter=KeSMSwAcsEntrySecRwLtStBkReclnUpwdDnwdPosMin.Val
          PA_KeSMSwAcsExtSecRwLtStBkReclnUpwdDnwdPos_Val: accessed-parameter=KeSMSwAcsExtSecRwLtStBkReclnUpwdDnwdPos.Val
          PA_KeSMSwAcsExtSecRwLtStBkReclnUpwdDnwdPosMax_Val: accessed-parameter=KeSMSwAcsExtSecRwLtStBkReclnUpwdDnwdPosMax.Val
          PA_KeSMSwAcsExtSecRwLtStBkReclnUpwdDnwdPosMin_Val: accessed-parameter=KeSMSwAcsExtSecRwLtStBkReclnUpwdDnwdPosMin.Val
          PA_KeSMSwAcsMd32SecRwLtStBkReclnUpwdDnwdPos_Val: accessed-parameter=KeSMSwAcsMd32SecRwLtStBkReclnUpwdDnwdPos.Val
          PA_KeSMSwAcsMd32SecRwLtStBkReclnUpwdDnwdPos1_Val: accessed-parameter=KeSMSwAcsMd32SecRwLtStBkReclnUpwdDnwdPos1.Val
          PA_KeSMSwAcsMd32SecRwLtStBkReclnUpwdDnwdPos1Max_Val: accessed-parameter=KeSMSwAcsMd32SecRwLtStBkReclnUpwdDnwdPos1Max.Val
          PA_KeSMSwAcsMd32SecRwLtStBkReclnUpwdDnwdPos1Min_Val: accessed-parameter=KeSMSwAcsMd32SecRwLtStBkReclnUpwdDnwdPos1Min.Val
          PA_KeSMSwAcsMd32SecRwLtStBkReclnUpwdDnwdPosMax_Val: accessed-parameter=KeSMSwAcsMd32SecRwLtStBkReclnUpwdDnwdPosMax.Val
          PA_KeSMSwAcsMd32SecRwLtStBkReclnUpwdDnwdPosMin_Val: accessed-parameter=KeSMSwAcsMd32SecRwLtStBkReclnUpwdDnwdPosMin.Val
          PA_KeSMSwAcsMd8SecRwLtStBkReclnUpwdDnwdPos_Val: accessed-parameter=KeSMSwAcsMd8SecRwLtStBkReclnUpwdDnwdPos.Val
          PA_KeSMSwAcsMd8SecRwLtStBkReclnUpwdDnwdPosMax_Val: accessed-parameter=KeSMSwAcsMd8SecRwLtStBkReclnUpwdDnwdPosMax.Val
          PA_KeSMSwAcsMd8SecRwLtStBkReclnUpwdDnwdPosMin_Val: accessed-parameter=KeSMSwAcsMd8SecRwLtStBkReclnUpwdDnwdPosMin.Val
          PA_KeSMSwRecoveryMdSecRwLtStBkReclnUpwdDnwdPos_Val: accessed-parameter=KeSMSwRecoveryMdSecRwLtStBkReclnUpwdDnwdPos.Val
          PA_KeSMSwRecoveryMdSecRwLtStBkReclnUpwdDnwdPosMax_Val: accessed-parameter=KeSMSwRecoveryMdSecRwLtStBkReclnUpwdDnwdPosMax.Val
          PA_KeSMSwRecoveryMdSecRwLtStBkReclnUpwdDnwdPosMin_Val: accessed-parameter=KeSMSwRecoveryMdSecRwLtStBkReclnUpwdDnwdPosMin.Val
          PA_KeSMSwVIPSecRwLtStBkReclnUpwdDnwdPos_Val: accessed-parameter=KeSMSwVIPSecRwLtStBkReclnUpwdDnwdPos.Val
          PA_KeSMSwVIPSecRwLtStBkReclnUpwdDnwdPosMax_Val: accessed-parameter=KeSMSwVIPSecRwLtStBkReclnUpwdDnwdPosMax.Val
          PA_KeSMSwVIPSecRwLtStBkReclnUpwdDnwdPosMin_Val: accessed-parameter=KeSMSwVIPSecRwLtStBkReclnUpwdDnwdPosMin.Val
  swc implementation SecRwLtStBkReclnTrgtPosSelc_Implementation: behavior=SecRwLtStBkReclnTrgtPosSelc_InternalBehavior
    code-descriptors:
      code Default: artifact-descriptors=autosar-engineering-object={short-label=Default, category=SWSRC}
package /PATAC/MSM/ModeAdjust/CalPortInterface
  16 x parameter interface:
    KeSMSw4SAcsMd21SecRwLtStBkReclnUpwdDnwdPos
      parameter data prototype Val: sw-calibration-access=READ-WRITE, type=UInt16
    KeSMSw4SAcsMd21SecRwLtStBkReclnUpwdDnwdPosMax
      parameter data prototype Val: sw-calibration-access=READ-WRITE, type=UInt16
    KeSMSw4SAcsMd21SecRwLtStBkReclnUpwdDnwdPosMin
      parameter data prototype Val: sw-calibration-access=READ-WRITE, type=UInt16
    KeSMSw4SAcsMd22SecRwLtStBkReclnUpwdDnwdPos1
      parameter data prototype Val: sw-calibration-access=READ-WRITE, type=UInt16
    KeSMSw4SAcsMd22SecRwLtStBkReclnUpwdDnwdPos1Max
      parameter data prototype Val: sw-calibration-access=READ-WRITE, type=UInt16
    KeSMSw4SAcsMd22SecRwLtStBkReclnUpwdDnwdPos1Min
      parameter data prototype Val: sw-calibration-access=READ-WRITE, type=UInt16
    KeSMSw4SAcsMd22SecRwLtStBkReclnUpwdDnwdPos2
      parameter data prototype Val: sw-calibration-access=READ-WRITE, type=UInt16
    KeSMSw4SAcsMd22SecRwLtStBkReclnUpwdDnwdPos2Max
      parameter data prototype Val: sw-calibration-access=READ-WRITE, type=UInt16
    KeSMSw4SAcsMd22SecRwLtStBkReclnUpwdDnwdPos2Min
      parameter data prototype Val: sw-calibration-access=READ-WRITE, type=UInt16
    KeSMSw4SAcsMd25SecRwLtStBkReclnUpwdDnwdPos
      parameter data prototype Val: sw-calibration-access=READ-WRITE, type=UInt16
    KeSMSw4SAcsMd25SecRwLtStBkReclnUpwdDnwdPosMax
      parameter data prototype Val: sw-calibration-access=READ-WRITE, type=UInt16
    KeSMSw4SAcsMd25SecRwLtStBkReclnUpwdDnwdPosMin
      parameter data prototype Val: sw-calibration-access=READ-WRITE, type=UInt16
    KeSMSw4SAcsMd26SecRwLtStBkReclnUpwdDnwdPos
      parameter data prototype Val: sw-calibration-access=READ-WRITE, type=UInt16
    KeSMSw4SAcsMd26SecRwLtStBkReclnUpwdDnwdPosMax
      parameter data prototype Val: sw-calibration-access=READ-WRITE, type=UInt16
    KeSMSw4SAcsMd26SecRwLtStBkReclnUpwdDnwdPosMin
      parameter data prototype Val: sw-calibration-access=READ-WRITE, type=UInt16
    Pos
      parameter data prototype Val: sw-calibration-access=READ-WRITE, type=UInt16
package /PATAC/MSM/ModeAdjust/DataType
  impl type TrgtPosCalibArray: category=ARRAY, sw-calibration-access=READ-ONLY, type-emitter=RTE  # 0:pos 1:max 2:min
    element Element: array-size=3, array-size-semantics=FIXED-SIZE, implementation-data-type=UInt16, invalid-value=0
package /PATAC/MSM/ModeAdjust/Interfaces
  sender receiver interface IfVeSMSuThdRwLtStCshnFldUpwdDnwdPos: invalidation-policy{data-element=IfVeSMSuThdRwLtStCshnFldUpwdDnwdPos/Val, handle-invalid=DONT-INVALIDATE}
    data Val: type=UInt16
package /PATAC/MSM/ModeAdjust/PortInterface
  client server interface SecRwLtStBkReclnTrgtPosSelc
    operation Cal
  client server interface VIPL557TrgtPos
    operation Get
      5 x arg, all with type=UInt16, direction=OUT, server-argument-impl-policy=USE-ARGUMENT-TYPE:
        SecRwLtStBkReclnTrgtPos
        SecRwLtStZeroTrgtPos
        SecRwLtStLgrstUpwdDnwdTrgtPos
        SecRwLtStLgrstInwdOtwdTrgtPos
        SecRwLtStFwdBkwdTrgtPos
    operation Set
      5 x arg, all with type=UInt16, direction=IN, server-argument-impl-policy=USE-ARGUMENT-TYPE:
        SecRwLtStBkReclnTrgtPos
        SecRwLtStZeroTrgtPos
        SecRwLtStLgrstUpwdDnwdTrgtPos
        SecRwLtStLgrstInwdOtwdTrgtPos
        SecRwLtStFwdBkwdTrgtPos
  client server interface VIPLExit557TrgtPos
    operation Get
      7 x arg, all with type=UInt16, direction=OUT, server-argument-impl-policy=USE-ARGUMENT-TYPE:
        SecRwLtStBkReclnTrgtPos
        SecRwLtStZeroTrgtPos
        SecRwLtStLgrstUpwdDnwdTrgtPos
        SecRwLtStLgrstInwdOtwdTrgtPos
        ThdRwLtStBkReclnTrgtPos
        ThdRwLtStFwdBkwdTrgtPos
        SecRwLtStFwdBkwdTrgtPos
    operation Set
  6 x sender receiver interface:
    MdSeatOccupied: invalidation-policy{data-element=MdSeatOccupied/Val, handle-invalid=DONT-INVALIDATE}
      data Val: type=Boolean
    modestate32: invalidation-policy{data-element=modestate32/Val, handle-invalid=DONT-INVALIDATE}
      data Val: type=UInt32
    R2LBkReclinFirstStepPassFlg: invalidation-policy{data-element=R2LBkReclinFirstStepPassFlg/Val, handle-invalid=DONT-INVALIDATE}
      data Val: type=Boolean
    StgDone: invalidation-policy{data-element=StgDone/Val, handle-invalid=DONT-INVALIDATE}
      data Val: type=Boolean
    StNumFlg
      4 x data, all with type=Boolean:
        Is4s
        Is6s
        Is6s7s
        Is7s
      invalidation-policys:
        data-element=Is4s, handle-invalid=DONT-INVALIDATE
        data-element=Is6s, handle-invalid=DONT-INVALIDATE
        data-element=Is6s7s, handle-invalid=DONT-INVALIDATE
        data-element=Is7s, handle-invalid=DONT-INVALIDATE
    TrgtPosCalibArray: invalidation-policy{data-element=TrgtPosArray, handle-invalid=DONT-INVALIDATE}
      data TrgtPosArray: type=TrgtPosCalibArray  # 0:Pos 1:Max 2:Min
package /PATAC/MSM/PortInterfaces
  sender receiver interface IfVeSMSbSecRwLtStCshnFrntUpwdDnwdMovConfig: invalidation-policy{data-element=IfVeSMSbSecRwLtStCshnFrntUpwdDnwdMovConfig/Val, handle-invalid=DONT-INVALIDATE}
    data Val: type=Boolean
